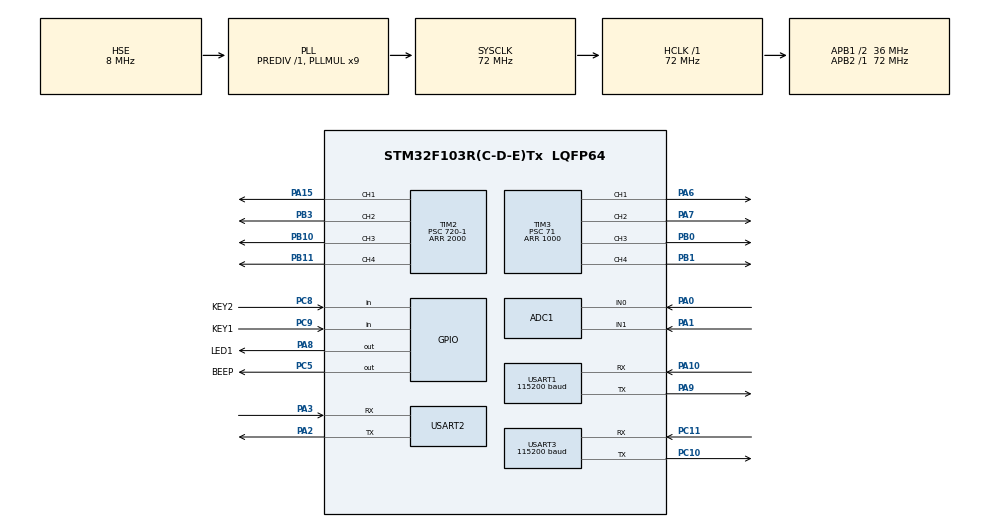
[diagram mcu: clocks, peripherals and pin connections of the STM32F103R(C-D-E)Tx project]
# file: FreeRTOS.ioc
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ADC1.Channel-0\#ChannelRegularConversion=ADC_CHANNEL_0
ADC1.NbrOfConversionFlag=1
ADC1.Rank-0\#ChannelRegularConversion=1
ADC1.SamplingTime-0\#ChannelRegularConversion=ADC_SAMPLETIME_1CYCLE_5
ADC1.master=1
Dma.Request0=USART2_RX
Dma.Request1=USART3_RX
Dma.Request2=USART1_TX
Dma.Request3=USART1_RX
Dma.USART1_RX.3.Direction=DMA_PERIPH_TO_MEMORY
Dma.USART1_RX.3.Instance=DMA1_Channel5
Dma.USART1_RX.3.MemDataAlignment=DMA_MDATAALIGN_BYTE
Dma.USART1_RX.3.MemInc=DMA_MINC_ENABLE
Dma.USART1_RX.3.Mode=DMA_NORMAL
Dma.USART1_RX.3.PeriphDataAlignment=DMA_PDATAALIGN_BYTE
Dma.USART1_RX.3.PeriphInc=DMA_PINC_DISABLE
Dma.USART1_RX.3.Priority=DMA_PRIORITY_VERY_HIGH
Dma.USART1_TX.2.Direction=DMA_MEMORY_TO_PERIPH
Dma.USART1_TX.2.Instance=DMA1_Channel4
Dma.USART1_TX.2.MemDataAlignment=DMA_MDATAALIGN_BYTE
Dma.USART1_TX.2.MemInc=DMA_MINC_ENABLE
Dma.USART1_TX.2.Mode=DMA_NORMAL
Dma.USART1_TX.2.PeriphDataAlignment=DMA_PDATAALIGN_BYTE
Dma.USART1_TX.2.PeriphInc=DMA_PINC_DISABLE
Dma.USART1_TX.2.Priority=DMA_PRIORITY_HIGH
Dma.USART2_RX.0.Direction=DMA_PERIPH_TO_MEMORY
Dma.USART2_RX.0.Instance=DMA1_Channel6
Dma.USART2_RX.0.MemDataAlignment=DMA_MDATAALIGN_BYTE
Dma.USART2_RX.0.MemInc=DMA_MINC_ENABLE
Dma.USART2_RX.0.Mode=DMA_NORMAL
Dma.USART2_RX.0.PeriphDataAlignment=DMA_PDATAALIGN_BYTE
Dma.USART2_RX.0.PeriphInc=DMA_PINC_DISABLE
Dma.USART2_RX.0.Priority=DMA_PRIORITY_VERY_HIGH
Dma.USART3_RX.1.Direction=DMA_PERIPH_TO_MEMORY
Dma.USART3_RX.1.Instance=DMA1_Channel3
Dma.USART3_RX.1.MemDataAlignment=DMA_MDATAALIGN_BYTE
Dma.USART3_RX.1.MemInc=DMA_MINC_ENABLE
Dma.USART3_RX.1.Mode=DMA_NORMAL
Dma.USART3_RX.1.PeriphDataAlignment=DMA_PDATAALIGN_BYTE
Dma.USART3_RX.1.PeriphInc=DMA_PINC_DISABLE
Dma.USART3_RX.1.Priority=DMA_PRIORITY_VERY_HIGH
FREERTOS.Queues01=uart_queue,16,void *,0,Dynamic,NULL,NULL
FREERTOS.Tasks01=defaultTask,0,256,StartDefaultTask,Default,NULL,Dynamic,NULL,NULL;myTask_BEEP,-3,128,StartTask_BEEP,Default,NULL,Dynamic,NULL,NULL;myTask_KEY,-3,128,StartTask_KEY,Default,NULL,Dynamic,NULL,NULL
FREERTOS.configMINIMAL_STACK_SIZE=128
FREERTOS.configUSE_NEWLIB_REENTRANT=1
Mcu.Family=STM32F1
Mcu.Name=STM32F103R(C-D-E)Tx
Mcu.Package=LQFP64
NVIC.DMA1_Channel3_IRQn=true\:5\:0\:false\:false\:true\:true\:false\:true\:true
NVIC.DMA1_Channel4_IRQn=true\:5\:0\:false\:false\:true\:true\:false\:true\:true
NVIC.DMA1_Channel5_IRQn=true\:5\:0\:false\:false\:true\:true\:false\:true\:true
NVIC.DMA1_Channel6_IRQn=true\:5\:0\:false\:false\:true\:true\:false\:true\:true
NVIC.PriorityGroup=NVIC_PRIORITYGROUP_4
NVIC.TIM6_IRQn=true\:15\:0\:false\:false\:true\:false\:false\:true\:true
NVIC.TimeBase=TIM6_IRQn
NVIC.TimeBaseIP=TIM6
NVIC.USART1_IRQn=true\:5\:0\:true\:false\:true\:true\:true\:true\:true
NVIC.USART2_IRQn=true\:5\:0\:false\:false\:true\:true\:true\:true\:true
NVIC.USART3_IRQn=true\:5\:0\:false\:false\:true\:true\:true\:true\:true
PA0-WKUP.Signal=ADCx_IN0
PA1.Signal=ADCx_IN1
PA10.GPIO_PuPd=GPIO_PULLUP
PA10.Mode=Asynchronous
PA10.Signal=USART1_RX
PA13.Mode=Serial_Wire
PA13.Signal=SYS_JTMS-SWDIO
PA14.Mode=Serial_Wire
PA14.Signal=SYS_JTCK-SWCLK
PA15.Signal=S_TIM2_CH1_ETR
PA2.Mode=Asynchronous
PA2.Signal=USART2_TX
PA3.GPIO_PuPd=GPIO_PULLUP
PA3.Mode=Asynchronous
PA3.Signal=USART2_RX
PA6.Signal=S_TIM3_CH1
PA7.Signal=S_TIM3_CH2
PA8.GPIO_Label=LED1
PA8.Signal=GPIO_Output
PA9.Mode=Asynchronous
PA9.Signal=USART1_TX
PB0.Signal=S_TIM3_CH3
PB1.Signal=S_TIM3_CH4
PB10.Signal=S_TIM2_CH3
PB11.Signal=S_TIM2_CH4
PB3.Signal=S_TIM2_CH2
PC10.Mode=Asynchronous
PC10.Signal=USART3_TX
PC11.GPIO_PuPd=GPIO_PULLUP
PC11.Mode=Asynchronous
PC11.Signal=USART3_RX
PC5.GPIO_Label=BEEP
PC5.Signal=GPIO_Output
PC8.GPIO_Label=KEY2
PC8.Signal=GPIO_Input
PC9.GPIO_Label=KEY1
PC9.GPIO_PuPd=GPIO_PULLUP
PC9.Signal=GPIO_Input
PD0-OSC_IN.Mode=HSE-External-Oscillator
PD0-OSC_IN.Signal=RCC_OSC_IN
PD1-OSC_OUT.Mode=HSE-External-Oscillator
PD1-OSC_OUT.Signal=RCC_OSC_OUT
ProjectManager.HeapSize=0x200
ProjectManager.StackSize=0x400
ProjectManager.TargetToolchain=STM32CubeIDE
RCC.ADCPresc=RCC_ADCPCLK2_DIV6
RCC.AHBFreq_Value=72000000
RCC.APB1CLKDivider=RCC_HCLK_DIV2
RCC.APB1Freq_Value=36000000
RCC.APB1TimFreq_Value=72000000
RCC.APB2Freq_Value=72000000
RCC.APB2TimFreq_Value=72000000
RCC.HCLKFreq_Value=72000000
RCC.PLLMUL=RCC_PLL_MUL9
RCC.PLLSourceVirtual=RCC_PLLSOURCE_HSE
RCC.SYSCLKFreq_VALUE=72000000
RCC.SYSCLKSource=RCC_SYSCLKSOURCE_PLLCLK
RCC.USBFreq_Value=72000000
SH.ADCx_IN0.0=ADC1_IN0,IN0
SH.ADCx_IN1.0=ADC1_IN1,IN1
SH.S_TIM2_CH1_ETR.0=TIM2_CH1,PWM Generation1 CH1
SH.S_TIM2_CH2.0=TIM2_CH2,PWM Generation2 CH2
SH.S_TIM2_CH3.0=TIM2_CH3,PWM Generation3 CH3
SH.S_TIM2_CH4.0=TIM2_CH4,PWM Generation4 CH4
SH.S_TIM3_CH1.0=TIM3_CH1,PWM Generation1 CH1
SH.S_TIM3_CH2.0=TIM3_CH2,PWM Generation2 CH2
SH.S_TIM3_CH3.0=TIM3_CH3,PWM Generation3 CH3
SH.S_TIM3_CH4.0=TIM3_CH4,PWM Generation4 CH4
TIM2.Channel-PWM\ Generation1\ CH1=TIM_CHANNEL_1
TIM2.Channel-PWM\ Generation2\ CH2=TIM_CHANNEL_2
TIM2.Channel-PWM\ Generation3\ CH3=TIM_CHANNEL_3
TIM2.Channel-PWM\ Generation4\ CH4=TIM_CHANNEL_4
TIM2.Period=2000
TIM2.Prescaler=720-1
TIM3.Channel-PWM\ Generation1\ CH1=TIM_CHANNEL_1
TIM3.Channel-PWM\ Generation2\ CH2=TIM_CHANNEL_2
TIM3.Channel-PWM\ Generation3\ CH3=TIM_CHANNEL_3
TIM3.Channel-PWM\ Generation4\ CH4=TIM_CHANNEL_4
TIM3.Period=1000
TIM3.Prescaler=71
USART1.BaudRate=115200
USART1.VirtualMode=VM_ASYNC
USART2.VirtualMode=VM_ASYNC
USART3.BaudRate=115200
USART3.VirtualMode=VM_ASYNC
VP_FREERTOS_VS_CMSIS_V1.Mode=CMSIS_V1
VP_SYS_VS_tim6.Mode=TIM6
VP_TIM2_VS_ClockSourceINT.Mode=Internal
VP_TIM3_VS_ClockSourceINT.Mode=Internal
board=custom

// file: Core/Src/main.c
/* USER CODE BEGIN Header */
/**
  ******************************************************************************
  * @file           : main.c
  * @brief          : Main program body
  ******************************************************************************
  * @attention
  *
  * Copyright (c) 2022 STMicroelectronics.
  * All rights reserved.
  *
  * This software is licensed under terms that can be found in the LICENSE file
  * in the root directory of this software component.
  * If no LICENSE file comes with this software, it is provided AS-IS.
  *
  ******************************************************************************
  */
/* USER CODE END Header */
#include "main.h"
#include "cmsis_os.h"
#include "adc.h"
#include "dma.h"
#include "tim.h"
#include "usart.h"
#include "gpio.h"

/* USER CODE BEGIN PTD */
#include "bsp.h"
/* USER CODE END PTD */

void SystemClock_Config(void);
void MX_FREERTOS_Init(void);

int main(void)
{

  /* MCU Configuration--------------------------------------------------------*/

  /* Reset of all peripherals, Initializes the Flash interface and the Systick. */
  HAL_Init();

  /* Configure the system clock */
  SystemClock_Config();

  /* Initialize all configured peripherals */
  MX_GPIO_Init();
  MX_USART1_UART_Init();
  MX_USART2_UART_Init();
  MX_USART3_UART_Init();
  MX_DMA_Init();
  MX_ADC1_Init();
  MX_TIM2_Init();
  MX_TIM3_Init();
  /* USER CODE BEGIN 2 */
  Bsp_Init();
  /* USER CODE END 2 */

  /* Call init function for freertos objects (in freertos.c) */
  MX_FREERTOS_Init();

  /* Start scheduler */
  osKernelStart();

  /* We should never get here as control is now taken by the scheduler */
  /* Infinite loop */
  while (1)
  {

  }
}

void SystemClock_Config(void)
{
  RCC_OscInitTypeDef RCC_OscInitStruct = {0};
  RCC_ClkInitTypeDef RCC_ClkInitStruct = {0};
  RCC_PeriphCLKInitTypeDef PeriphClkInit = {0};

  /** Initializes the RCC Oscillators according to the specified parameters
  * in the RCC_OscInitTypeDef structure.
  */
  RCC_OscInitStruct.OscillatorType = RCC_OSCILLATORTYPE_HSE;
  RCC_OscInitStruct.HSEState = RCC_HSE_ON;
  RCC_OscInitStruct.HSEPredivValue = RCC_HSE_PREDIV_DIV1;
  RCC_OscInitStruct.HSIState = RCC_HSI_ON;
  RCC_OscInitStruct.PLL.PLLState = RCC_PLL_ON;
  RCC_OscInitStruct.PLL.PLLSource = RCC_PLLSOURCE_HSE;
  RCC_OscInitStruct.PLL.PLLMUL = RCC_PLL_MUL9;
  if (HAL_RCC_OscConfig(&RCC_OscInitStruct) != HAL_OK)
  {
    Error_Handler();
  }

  /** Initializes the CPU, AHB and APB buses clocks
  */
  RCC_ClkInitStruct.ClockType = RCC_CLOCKTYPE_HCLK|RCC_CLOCKTYPE_SYSCLK
                              |RCC_CLOCKTYPE_PCLK1|RCC_CLOCKTYPE_PCLK2;
  RCC_ClkInitStruct.SYSCLKSource = RCC_SYSCLKSOURCE_PLLCLK;
  RCC_ClkInitStruct.AHBCLKDivider = RCC_SYSCLK_DIV1;
  RCC_ClkInitStruct.APB1CLKDivider = RCC_HCLK_DIV2;
  RCC_ClkInitStruct.APB2CLKDivider = RCC_HCLK_DIV1;

  if (HAL_RCC_ClockConfig(&RCC_ClkInitStruct, FLASH_LATENCY_2) != HAL_OK)
  {
    Error_Handler();
  }
  PeriphClkInit.PeriphClockSelection = RCC_PERIPHCLK_ADC;
  PeriphClkInit.AdcClockSelection = RCC_ADCPCLK2_DIV6;
  if (HAL_RCCEx_PeriphCLKConfig(&PeriphClkInit) != HAL_OK)
  {
    Error_Handler();
  }
}

void HAL_TIM_PeriodElapsedCallback(TIM_HandleTypeDef *htim)
{
  if (htim->Instance == TIM6) {
    HAL_IncTick();
  }
}

void Error_Handler(void)
{
  __disable_irq();
  while (1)
  {
  }
}
